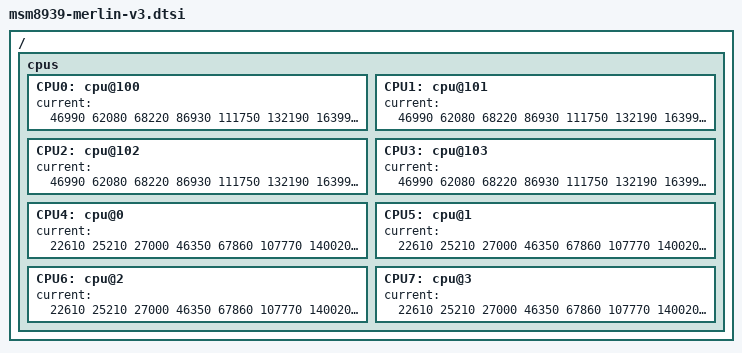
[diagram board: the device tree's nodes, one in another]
/* Copyright (c) 2015, Motorola Mobility LLC. All rights reserved.
*
* This program is free software; you can redistribute it and/or modify
* it under the terms of the GNU General Public License version 2 and
* only version 2 as published by the Free Software Foundation.
*
* This program is distributed in the hope that it will be useful,
* but WITHOUT ANY WARRANTY; without even the implied warranty of
* MERCHANTABILITY or FITNESS FOR A PARTICULAR PURPOSE.  See the
* GNU General Public License for more details.
*/


/memreserve/ 0xaf000000 0x00080000;

#include "msm8939-v3.0.dtsi"
#include "msm8939-merlin-common.dtsi"
/ {
	cpus {
		CPU0: cpu@100 {
			current = < 46990 //200000 kHz
			62080 //345600 kHz
			68220 //400000 kHz
			86930 //533333 kHz
			111750 //800000 kHz
			132190 //960000 kHz
			163990 //1113600 kHz
			228640 //1344000 kHz
			277260 //1459200 kHz
			289260>; //1497600 kHz
		};
		CPU1: cpu@101 {
			current = < 46990 //200000 kHz
			62080 //345600 kHz
			68220 //400000 kHz
			86930 //533333 kHz
			111750 //800000 kHz
			132190 //960000 kHz
			163990 //1113600 kHz
			228640 //1344000 kHz
			277260 //1459200 kHz
			289260>; //1497600 kHz
		};
		CPU2: cpu@102 {
			current = < 46990 //200000 kHz
			62080 //345600 kHz
			68220 //400000 kHz
			86930 //533333 kHz
			111750 //800000 kHz
			132190 //960000 kHz
			163990 //1113600 kHz
			228640 //1344000 kHz
			277260 //1459200 kHz
			289260>; //1497600 kHz
		};
		CPU3: cpu@103 {
			current = < 46990 //200000 kHz
			62080 //345600 kHz
			68220 //400000 kHz
			86930 //533333 kHz
			111750 //800000 kHz
			132190 //960000 kHz
			163990 //1113600 kHz
			228640 //1344000 kHz
			277260 //1459200 kHz
			289260>; //1497600 kHz
		};
		CPU4: cpu@0 {
			current = < 22610 //200000 kHz
			25210 //249600 kHz
			27000 //400000 kHz
			46350 //533333 kHz
			67860 //800000 kHz
			107770 //998400 kHz
			140020 //1113600 kHz
			160020>; //1209600 kHz
		};
		CPU5: cpu@1 {
			current = < 22610 //200000 kHz
			25210 //249600 kHz
			27000 //400000 kHz
			46350 //533333 kHz
			67860 //800000 kHz
			107770 //998400 kHz
			140020 //1113600 kHz
			160020>; //1209600 kHz
		};
		CPU6: cpu@2 {
			current = < 22610 //200000 kHz
			25210 //249600 kHz
			27000 //400000 kHz
			46350 //533333 kHz
			67860 //800000 kHz
			107770 //998400 kHz
			140020 //1113600 kHz
			160020>; //1209600 kHz
		};
		CPU7: cpu@3 {
			current = < 22610 //200000 kHz
			25210 //249600 kHz
			27000 //400000 kHz
			46350 //533333 kHz
			67860 //800000 kHz
			107770 //998400 kHz
			140020 //1113600 kHz
			160020>; //1209600 kHz
		};
	};
};
